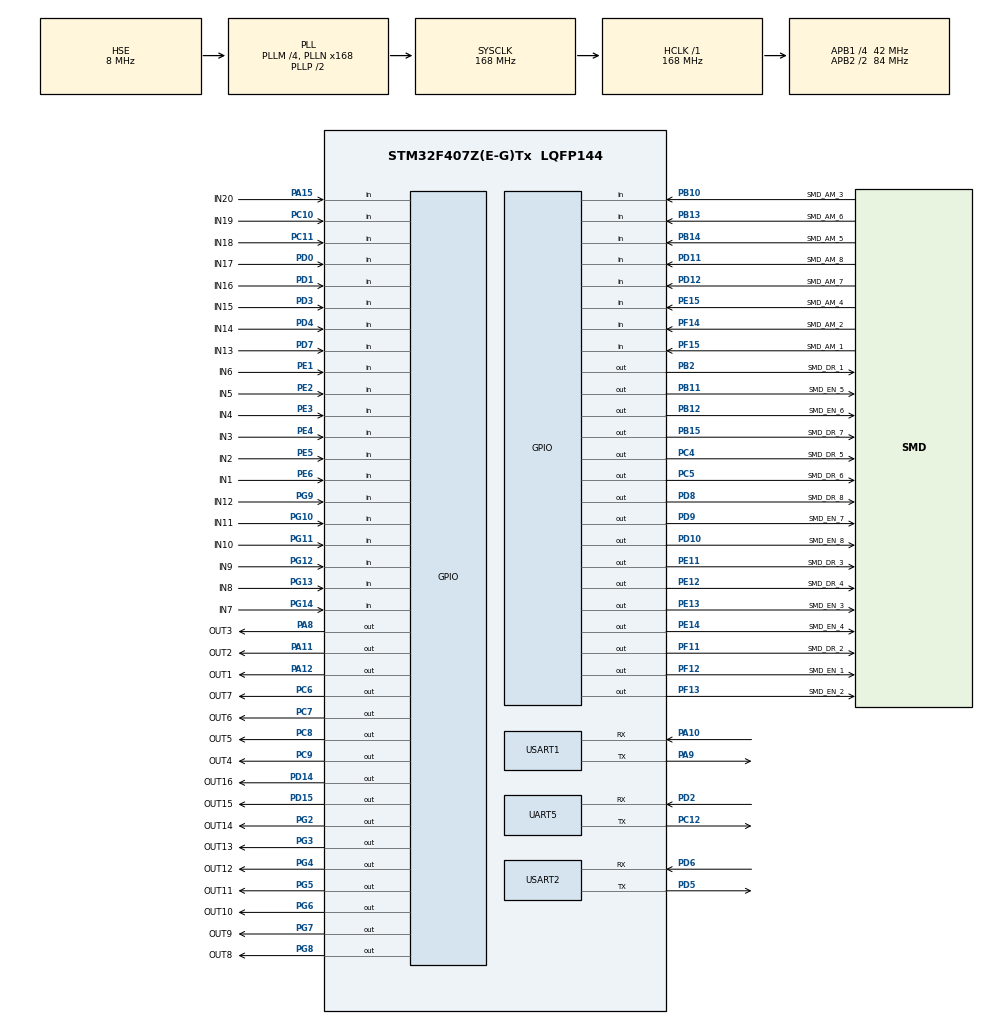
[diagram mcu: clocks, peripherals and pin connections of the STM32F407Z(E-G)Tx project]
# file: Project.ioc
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Mcu.Family=STM32F4
Mcu.Name=STM32F407Z(E-G)Tx
Mcu.Package=LQFP144
NVIC.PriorityGroup=NVIC_PRIORITYGROUP_4
NVIC.TIM6_DAC_IRQn=true\:0\:0\:false\:false\:false\:true\:true\:true
NVIC.TIM7_IRQn=true\:0\:0\:false\:false\:false\:true\:true\:true
NVIC.TIM8_BRK_TIM12_IRQn=true\:0\:0\:false\:false\:false\:true\:true\:true
NVIC.UART5_IRQn=true\:0\:0\:false\:false\:false\:true\:true\:true
NVIC.USART1_IRQn=true\:0\:0\:false\:false\:false\:true\:true\:true
NVIC.USART2_IRQn=true\:0\:0\:false\:false\:false\:true\:true\:true
PA10.Mode=Asynchronous
PA10.Signal=USART1_RX
PA11.GPIO_Label=OUT2
PA11.Signal=GPIO_Output
PA12.GPIO_Label=OUT1
PA12.Signal=GPIO_Output
PA13.Mode=Serial_Wire
PA13.Signal=SYS_JTMS-SWDIO
PA14.Mode=Serial_Wire
PA14.Signal=SYS_JTCK-SWCLK
PA15.GPIO_Label=IN20
PA15.Signal=GPIO_Input
PA8.GPIO_Label=OUT3
PA8.Signal=GPIO_Output
PA9.Mode=Asynchronous
PA9.Signal=USART1_TX
PB10.GPIO_Label=SMD_AM_3
PB10.Signal=GPIO_Input
PB11.GPIO_Label=SMD_EN_5
PB11.Signal=GPIO_Output
PB12.GPIO_Label=SMD_EN_6
PB12.Signal=GPIO_Output
PB13.GPIO_Label=SMD_AM_6
PB13.Signal=GPIO_Input
PB14.GPIO_Label=SMD_AM_5
PB14.Signal=GPIO_Input
PB15.GPIO_Label=SMD_DR_7
PB15.Signal=GPIO_Output
PB2.GPIO_Label=SMD_DR_1
PB2.Signal=GPIO_Output
PC10.GPIO_Label=IN19
PC10.Signal=GPIO_Input
PC11.GPIO_Label=IN18
PC11.Signal=GPIO_Input
PC12.Mode=Asynchronous
PC12.Signal=UART5_TX
PC4.GPIO_Label=SMD_DR_5
PC4.Signal=GPIO_Output
PC5.GPIO_Label=SMD_DR_6
PC5.Signal=GPIO_Output
PC6.GPIO_Label=OUT7
PC6.Signal=GPIO_Output
PC7.GPIO_Label=OUT6
PC7.Signal=GPIO_Output
PC8.GPIO_Label=OUT5
PC8.Signal=GPIO_Output
PC9.GPIO_Label=OUT4
PC9.Signal=GPIO_Output
PD0.GPIO_Label=IN17
PD0.Signal=GPIO_Input
PD1.GPIO_Label=IN16
PD1.Signal=GPIO_Input
PD10.GPIO_Label=SMD_EN_8
PD10.Signal=GPIO_Output
PD11.GPIO_Label=SMD_AM_8
PD11.Signal=GPIO_Input
PD12.GPIO_Label=SMD_AM_7
PD12.Signal=GPIO_Input
PD14.GPIO_Label=OUT16
PD14.Signal=GPIO_Output
PD15.GPIO_Label=OUT15
PD15.Signal=GPIO_Output
PD2.Mode=Asynchronous
PD2.Signal=UART5_RX
PD3.GPIO_Label=IN15
PD3.Signal=GPIO_Input
PD4.GPIO_Label=IN14
PD4.Signal=GPIO_Input
PD5.Mode=Asynchronous
PD5.Signal=USART2_TX
PD6.Mode=Asynchronous
PD6.Signal=USART2_RX
PD7.GPIO_Label=IN13
PD7.Signal=GPIO_Input
PD8.GPIO_Label=SMD_DR_8
PD8.Signal=GPIO_Output
PD9.GPIO_Label=SMD_EN_7
PD9.Signal=GPIO_Output
PE1.GPIO_Label=IN6
PE1.Signal=GPIO_Input
PE11.GPIO_Label=SMD_DR_3
PE11.Signal=GPIO_Output
PE12.GPIO_Label=SMD_DR_4
PE12.Signal=GPIO_Output
PE13.GPIO_Label=SMD_EN_3
PE13.Signal=GPIO_Output
PE14.GPIO_Label=SMD_EN_4
PE14.Signal=GPIO_Output
PE15.GPIO_Label=SMD_AM_4
PE15.Signal=GPIO_Input
PE2.GPIO_Label=IN5
PE2.Signal=GPIO_Input
PE3.GPIO_Label=IN4
PE3.Signal=GPIO_Input
PE4.GPIO_Label=IN3
PE4.Signal=GPIO_Input
PE5.GPIO_Label=IN2
PE5.Signal=GPIO_Input
PE6.GPIO_Label=IN1
PE6.Signal=GPIO_Input
PF11.GPIO_Label=SMD_DR_2
PF11.Signal=GPIO_Output
PF12.GPIO_Label=SMD_EN_1
PF12.Signal=GPIO_Output
PF13.GPIO_Label=SMD_EN_2
PF13.Signal=GPIO_Output
PF14.GPIO_Label=SMD_AM_2
PF14.Signal=GPIO_Input
PF15.GPIO_Label=SMD_AM_1
PF15.Signal=GPIO_Input
PG10.GPIO_Label=IN11
PG10.Signal=GPIO_Input
PG11.GPIO_Label=IN10
PG11.Signal=GPIO_Input
PG12.GPIO_Label=IN9
PG12.Signal=GPIO_Input
PG13.GPIO_Label=IN8
PG13.Signal=GPIO_Input
PG14.GPIO_Label=IN7
PG14.Signal=GPIO_Input
PG2.GPIO_Label=OUT14
PG2.Signal=GPIO_Output
PG3.GPIO_Label=OUT13
PG3.Signal=GPIO_Output
PG4.GPIO_Label=OUT12
PG4.Signal=GPIO_Output
PG5.GPIO_Label=OUT11
PG5.Signal=GPIO_Output
PG6.GPIO_Label=OUT10
PG6.Signal=GPIO_Output
PG7.GPIO_Label=OUT9
PG7.Signal=GPIO_Output
PG8.GPIO_Label=OUT8
PG8.Signal=GPIO_Output
PG9.GPIO_Label=IN12
PG9.Signal=GPIO_Input
PH0-OSC_IN.Mode=HSE-External-Oscillator
PH0-OSC_IN.Signal=RCC_OSC_IN
PH1-OSC_OUT.Mode=HSE-External-Oscillator
PH1-OSC_OUT.Signal=RCC_OSC_OUT
ProjectManager.HeapSize=0x200
ProjectManager.StackSize=0x400
ProjectManager.TargetToolchain=MDK-ARM V5.32
RCC.48MHZClocksFreq_Value=84000000
RCC.AHBFreq_Value=168000000
RCC.APB1CLKDivider=RCC_HCLK_DIV4
RCC.APB1Freq_Value=42000000
RCC.APB1TimFreq_Value=84000000
RCC.APB2CLKDivider=RCC_HCLK_DIV2
RCC.APB2Freq_Value=84000000
RCC.APB2TimFreq_Value=168000000
RCC.CortexFreq_Value=168000000
RCC.HCLKFreq_Value=168000000
RCC.HSE_VALUE=8000000
RCC.HSI_VALUE=16000000
RCC.LSE_VALUE=32768
RCC.PLLM=4
RCC.PLLN=168
RCC.PLLSourceVirtual=RCC_PLLSOURCE_HSE
RCC.SYSCLKFreq_VALUE=168000000
RCC.SYSCLKSource=RCC_SYSCLKSOURCE_PLLCLK
RCC.VCOOutputFreq_Value=336000000
UART5.VirtualMode=Asynchronous
USART1.VirtualMode=VM_ASYNC
USART2.VirtualMode=VM_ASYNC
VP_TIM12_VS_ClockSourceINT.Mode=Internal
VP_TIM6_VS_ClockSourceINT.Mode=Enable_Timer
VP_TIM7_VS_ClockSourceINT.Mode=Enable_Timer
board=custom

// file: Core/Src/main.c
/* USER CODE BEGIN Header */
/**
  ******************************************************************************
  * @file           : main.c
  * @brief          : Main program body
  ******************************************************************************
  * @attention
  *
  * Copyright (c) 2026 STMicroelectronics.
  * All rights reserved.
  *
  * This software is licensed under terms that can be found in the LICENSE file
  * in the root directory of this software component.
  * If no LICENSE file comes with this software, it is provided AS-IS.
  *
  ******************************************************************************
  */
/* USER CODE END Header */
#include "main.h"
#include "tim.h"
#include "usart.h"
#include "gpio.h"
#include "SMD.h"

/* USER CODE BEGIN Includes */
#include "mb_slave.h"
#include "mb_hook.h"
/* USER CODE END Includes */

void SystemClock_Config(void);

int main(void)
{

    /* MCU Configuration--------------------------------------------------------*/

    /* Reset of all peripherals, Initializes the Flash interface and the Systick. */
    HAL_Init();

    /* Configure the system clock */
    SystemClock_Config();

    /* Initialize all configured peripherals */
    MX_GPIO_Init();
    MX_USART1_UART_Init();
    MX_UART5_Init();
    MX_USART2_UART_Init();
    MX_TIM12_Init();
    MX_TIM6_Init();
    MX_TIM7_Init();
    /* USER CODE BEGIN 2 */
    mbsUSB.slaveAddr = 1;
    mbsUSB.baudRate = 115200;
    mbsUSB.parity = 0;

    mbsESP.slaveAddr = 1;
    mbsESP.baudRate = 115200;
    mbsESP.parity = 0;

    mbsSTM.slaveAddr = 1;
    mbsSTM.baudRate = 115200;
    mbsSTM.parity = 0;

    mbs_init(&mbsUSB);
    mbs_init(&mbsESP);
    mbs_init(&mbsSTM);

	SMD_PWM_InitAll();
    /* USER CODE END 2 */

    /* 初始化保持寄存器镜像，防止首次 Modbus 写触发 ACC clamp 到 1 */
    mbs_hook_updata_holding(&mbsUSB);
    mbs_hook_updata_holding(&mbsESP);
    mbs_hook_updata_holding(&mbsSTM);
    /* Infinite loop */
    while (1)
    {

        /* USER CODE BEGIN 3 */
        mbs_poll(&mbsUSB);
        mbs_poll(&mbsESP);
        mbs_poll(&mbsSTM);
    }

    /* USER CODE END 3 */
}

void SystemClock_Config(void)
{
    RCC_OscInitTypeDef RCC_OscInitStruct = {0};
    RCC_ClkInitTypeDef RCC_ClkInitStruct = {0};

    /** Configure the main internal regulator output voltage
    */
    __HAL_RCC_PWR_CLK_ENABLE();
    __HAL_PWR_VOLTAGESCALING_CONFIG(PWR_REGULATOR_VOLTAGE_SCALE1);

    /** Initializes the RCC Oscillators according to the specified parameters
    * in the RCC_OscInitTypeDef structure.
    */
    RCC_OscInitStruct.OscillatorType = RCC_OSCILLATORTYPE_HSE;
    RCC_OscInitStruct.HSEState = RCC_HSE_ON;
    RCC_OscInitStruct.PLL.PLLState = RCC_PLL_ON;
    RCC_OscInitStruct.PLL.PLLSource = RCC_PLLSOURCE_HSE;
    RCC_OscInitStruct.PLL.PLLM = 4;
    RCC_OscInitStruct.PLL.PLLN = 168;
    RCC_OscInitStruct.PLL.PLLP = RCC_PLLP_DIV2;
    RCC_OscInitStruct.PLL.PLLQ = 4;

    if (HAL_RCC_OscConfig(&RCC_OscInitStruct) != HAL_OK)
    {
        Error_Handler();
    }

    /** Initializes the CPU, AHB and APB buses clocks
    */
    RCC_ClkInitStruct.ClockType = RCC_CLOCKTYPE_HCLK | RCC_CLOCKTYPE_SYSCLK
                                  | RCC_CLOCKTYPE_PCLK1 | RCC_CLOCKTYPE_PCLK2;
    RCC_ClkInitStruct.SYSCLKSource = RCC_SYSCLKSOURCE_PLLCLK;
    RCC_ClkInitStruct.AHBCLKDivider = RCC_SYSCLK_DIV1;
    RCC_ClkInitStruct.APB1CLKDivider = RCC_HCLK_DIV4;
    RCC_ClkInitStruct.APB2CLKDivider = RCC_HCLK_DIV2;

    if (HAL_RCC_ClockConfig(&RCC_ClkInitStruct, FLASH_LATENCY_5) != HAL_OK)
    {
        Error_Handler();
    }
}

void Error_Handler(void)
{
    __disable_irq();
    while (1)
    {
    }
}
